VERSION "created by Milan Hutera"

NS_ :

BS_:

BU_: WorkGrp ECU Drive Display Primary PTOLKeypad ServiceTool Joystick1 Catalyst Shuttle Attachment CABKeypad ACDKeypad Joystick2 Joystick3

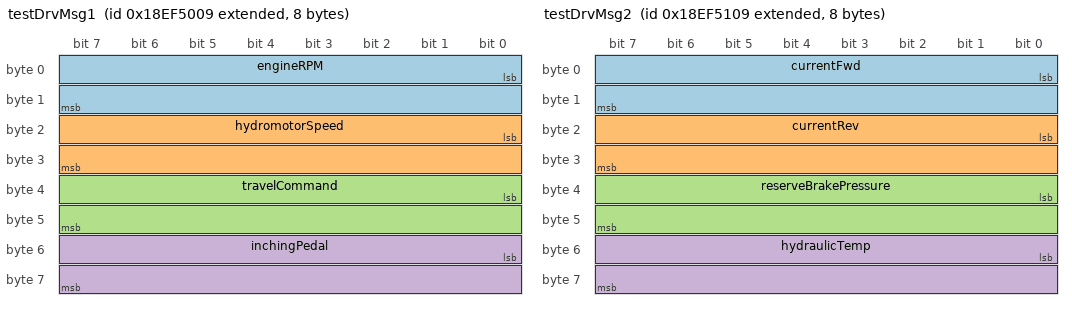
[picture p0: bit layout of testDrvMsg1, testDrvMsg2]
BO_ 2565820425 testDrvMsg1: 8 Drive
 SG_ engineRPM : 0|16@1+ (1,0.00) [0.00|65535.0] "-" ServiceTool
 SG_ hydromotorSpeed : 16|16@1+ (1,0.00) [0.00|65535.0] "-" ServiceTool
 SG_ travelCommand : 32|16@1+ (0.01,0.00) [0.00|655.35] "-" ServiceTool
 SG_ inchingPedal : 48|16@1+ (0.01,0.00) [0.00|655.35] "-" ServiceTool

BO_ 2565820681 testDrvMsg2: 8 Drive
 SG_ currentFwd : 0|16@1+ (0.01,0.00) [0.00|655.35] "-" ServiceTool
 SG_ currentRev : 16|16@1+ (0.01,0.00) [0.00|655.35] "-" ServiceTool
 SG_ reserveBrakePressure : 32|16@1+ (0.01,0.00) [0.00|655.35] "-" ServiceTool
 SG_ hydraulicTemp : 48|16@1+ (0.01,0.00) [0.00|655.35] "-" ServiceTool

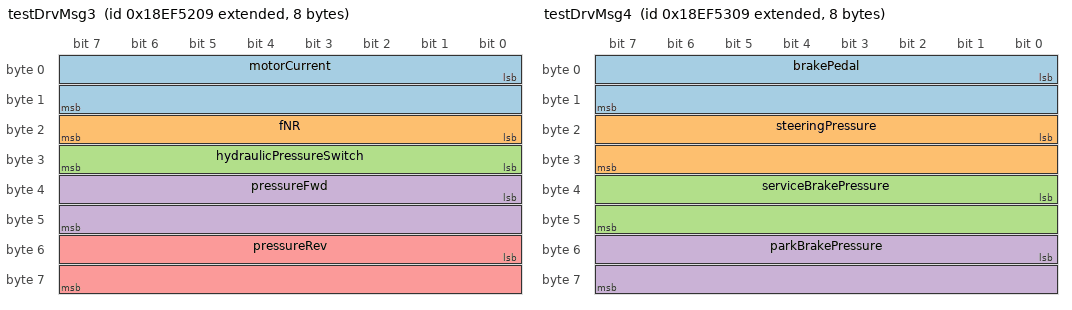
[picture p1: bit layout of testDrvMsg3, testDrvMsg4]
BO_ 2565820937 testDrvMsg3: 8 Drive
 SG_ motorCurrent : 0|16@1+ (0.01,0.00) [0.00|655.35] "-" ServiceTool
 SG_ fNR : 16|8@1+ (1,0.00) [0.00|255.0] "-" ServiceTool
 SG_ hydraulicPressureSwitch : 24|8@1+ (1,0.00) [0.00|255.0] "-" ServiceTool
 SG_ pressureFwd : 32|16@1+ (0.01,0.00) [0.00|655.35] "-" ServiceTool
 SG_ pressureRev : 48|16@1+ (0.01,0.00) [0.00|655.35] "-" ServiceTool

BO_ 2565821193 testDrvMsg4: 8 Drive
 SG_ brakePedal : 0|16@1+ (0.01,0.00) [0.00|655.35] "-" ServiceTool
 SG_ steeringPressure : 16|16@1+ (0.01,0.00) [0.00|655.35] "-" ServiceTool
 SG_ serviceBrakePressure : 32|16@1+ (0.01,0.00) [0.00|655.35] "-" ServiceTool
 SG_ parkBrakePressure : 48|16@1+ (0.01,0.00) [0.00|655.35] "-" ServiceTool

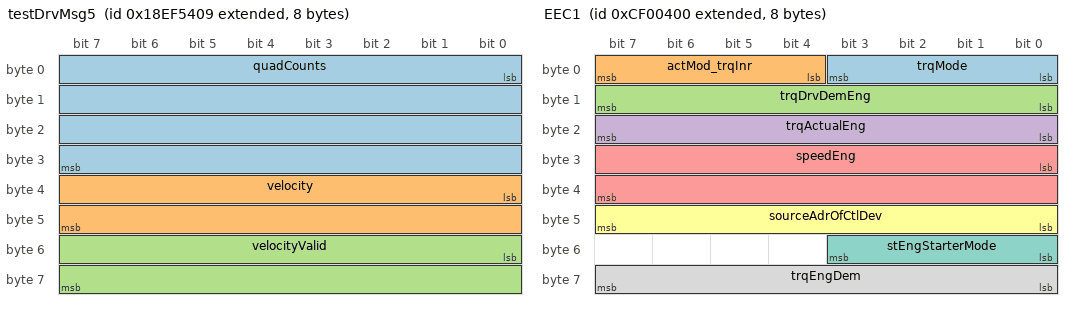
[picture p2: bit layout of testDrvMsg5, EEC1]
BO_ 2565821449 testDrvMsg5: 8 Drive
 SG_ quadCounts : 0|32@1+ (1.0,-2147483648) [-2147483648|21474] "-" ServiceTool
 SG_ velocity : 32|16@1+ (0.01,-60.00) [-60.00|60.00] "-" ServiceTool
 SG_ velocityValid : 48|16@1+ (0.01,0.00) [0.00|655.35] "-" ServiceTool

BO_ 2565821705 testDrvMsg6: 8 Drive
 SG_ quadErrorCounts : 0|32@1+ (1.0,-2147483648) [-2147483648|21474] "-" ServiceTool
 SG_ encoderACount : 32|32@1+ (1.0,-2147483648) [-2147483648|21474] "-" ServiceTool

BO_ 2364539904 EEC1: 8 ECU
 SG_ trqMode : 0|4@1+ (1,0) [0|0] "-" Primary
 SG_ actMod_trqInr : 4|4@1- (0.125,0.0) [0.0|0.875] "" Primary
 SG_ trqDrvDemEng : 8|8@1+ (1,-125.0) [-125.0|125.0] "%" Primary
 SG_ trqActualEng : 16|8@1+ (10.0,-1250.0) [-1250.0|1250.0] "Nm" Primary
 SG_ speedEng : 24|16@1+ (0.125,0.0) [0.0|8031.88] "" Primary
 SG_ sourceAdrOfCtlDev : 40|8@1+ (1,0) [0|0] "-" Primary
 SG_ stEngStarterMode : 48|4@1+ (1,0) [0|0] "-" Primary
 SG_ trqEngDem : 56|8@1+ (1,0.0) [0.0|125.0] "%" Primary

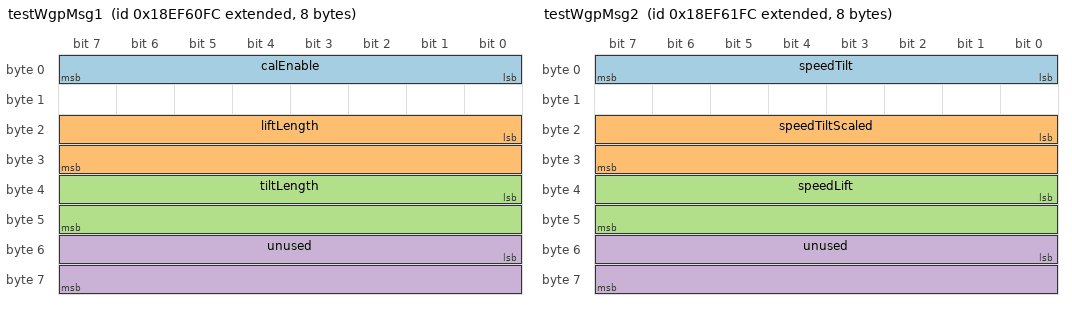
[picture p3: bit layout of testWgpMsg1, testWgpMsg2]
BO_ 2565824764 testWgpMsg1: 8 WorkGrp
 SG_ calEnable : 0|8@1+ (1,0.00) [0.00|255.0] "-" ServiceTool
 SG_ liftLength : 16|16@1+ (1,0.00) [0.00|65535.0] "-" ServiceTool
 SG_ tiltLength : 32|16@1+ (1,0.00) [0.00|65535.0] "-" ServiceTool
 SG_ unused : 48|16@1+ (0.01,0.00) [0.00|655.35] "-" ServiceTool

BO_ 2565825020 testWgpMsg2: 8 WorkGrp
 SG_ speedTilt : 0|8@1+ (1,0.00) [0.00|255.0] "-" ServiceTool
 SG_ speedTiltScaled : 16|16@1+ (0.1,0.00) [0.00|6553.5] "-" ServiceTool
 SG_ speedLift : 32|16@1+ (0.1,0.00) [0.00|6553.5] "-" ServiceTool
 SG_ unused : 48|16@1+ (0.01,0.00) [0.00|655.35] "-" ServiceTool

CM_ BO_ 2364539904 "Electronic Engine Control";

CM_ SG_ 2364539904 trqMode "Engine Torque Mode";
CM_ SG_ 2364539904 actMod_trqInr "Actual Engine : Percent Torque High Resolution";
CM_ SG_ 2364539904 trqDrvDemEng "Driver's Demand Engine : Percent Torque";
CM_ SG_ 2364539904 trqActualEng "Actual Engine : Percent Torque";
CM_ SG_ 2364539904 speedEng "Engine Speed";
CM_ SG_ 2364539904 sourceAdrOfCtlDev "Source Address of Controlling Device for Engine Control";
CM_ SG_ 2364539904 stEngStarterMode "Engine Starter mode";
CM_ SG_ 2364539904 trqEngDem "Engine Demand : Percent Torque";

BA_DEF_ SG_  "SigType" ENUM  "Default","Range","RangeSigned","ASCII","Discrete","Control","ReferencePGN","DTC","StringDelimiter","StringLength","StringLengthControl";
BA_DEF_ SG_  "GenSigEVName" STRING ;
BA_DEF_ SG_  "GenSigILSupport" ENUM  "No","Yes";
BA_DEF_ SG_  "GenSigSendType" ENUM  "Cyclic","OnWrite","OnWriteWithRepetition","OnChange","OnChangeWithRepetition","IfActive","IfActiveWithRepetition","NoSigSendType";
BA_DEF_ BO_  "GenMsgILSupport" ENUM  "No","Yes";
BA_DEF_ BU_  "NmStationAddress" INT 0 255;
BA_DEF_ BO_  "GenMsgSendType" ENUM  "cyclic","SendNow","IfActive","onRequest","Ident","counterValidator","NotUsed","NotUsed","noMsgSendType","enabled";
BA_DEF_ BO_  "Port_Drive" ENUM  "CAN_PORT_1","CAN_PORT_2","CAN_PORT_3","CAN_PORT_4","CAN_PORT_5","CAN_PORT_6","CAN_PORT_7","CAN_PORT_8","None";
BA_DEF_ BO_  "Port_ServiceTool" ENUM  "CAN_PORT_1","CAN_PORT_2","CAN_PORT_3","CAN_PORT_4","CAN_PORT_5","CAN_PORT_6","CAN_PORT_7","CAN_PORT_8","None";
BA_DEF_ BO_  "Port_ECU" ENUM  "CAN_PORT_1","CAN_PORT_2","CAN_PORT_3","CAN_PORT_4","CAN_PORT_5","CAN_PORT_6","CAN_PORT_7","CAN_PORT_8","None";
BA_DEF_ BO_  "Port_Primary" ENUM  "CAN_PORT_1","CAN_PORT_2","CAN_PORT_3","CAN_PORT_4","CAN_PORT_5","CAN_PORT_6","CAN_PORT_7","CAN_PORT_8","None";
BA_DEF_ BO_  "Port_WorkGrp" ENUM  "CAN_PORT_1","CAN_PORT_2","CAN_PORT_3","CAN_PORT_4","CAN_PORT_5","CAN_PORT_6","CAN_PORT_7","CAN_PORT_8","None";

BA_DEF_ BO_  "GenMsgRequestable" INT 0 1;
BA_DEF_ BO_  "GenMsgCycleTime" INT 0 3600000;
BA_DEF_  "DBName" STRING ;
BA_DEF_  "BusType" STRING ;
BA_DEF_  "ProtocolType" STRING ;
BA_DEF_ BO_  "VFrameFormat" ENUM  "StandardCAN","ExtendedCAN","reserved","J1939PG";
BA_DEF_DEF_  "SigType" "Default";
BA_DEF_DEF_  "GenSigEVName" "Env@Nodename_@Signame";
BA_DEF_DEF_  "GenSigILSupport" "Yes";
BA_DEF_DEF_  "GenSigSendType" "NoSigSendType";
BA_DEF_DEF_  "Port_Drive" "None";
BA_DEF_DEF_  "Port_ServiceTool" "None";
BA_DEF_DEF_  "Port_ECU" "None";
BA_DEF_DEF_  "Port_Primary" "None";
BA_DEF_DEF_  "Port_WorkGrp" "None";

BA_DEF_DEF_  "GenMsgILSupport" "Yes";
BA_DEF_DEF_  "NmStationAddress" 254;
BA_DEF_DEF_  "GenMsgSendType" "noMsgSendType";
BA_DEF_DEF_  "GenMsgRequestable" 1;
BA_DEF_DEF_  "GenMsgCycleTime" 0;
BA_DEF_DEF_  "DBName" "";
BA_DEF_DEF_  "BusType" "CAN";
BA_DEF_DEF_  "ProtocolType" "J1939";
BA_DEF_DEF_  "VFrameFormat" "J1939PG";
BA_ "DBName" "CWL";
BA_ "NmStationAddress" BU_ WorkGrp 252;
BA_ "NmStationAddress" BU_ ECU 0;
BA_ "NmStationAddress" BU_ Drive 9;
BA_ "NmStationAddress" BU_ Display 65;
BA_ "NmStationAddress" BU_ Primary 176;
BA_ "NmStationAddress" BU_ PTOLKeypad 55;
BA_ "NmStationAddress" BU_ ServiceTool 179;
BA_ "NmStationAddress" BU_ Joystick1 236;
BA_ "NmStationAddress" BU_ Catalyst 163;
BA_ "NmStationAddress" BU_ Shuttle 240;
BA_ "NmStationAddress" BU_ Attachment 180;
BA_ "NmStationAddress" BU_ CABKeypad 194;
BA_ "NmStationAddress" BU_ ACDKeypad 195;
BA_ "NmStationAddress" BU_ Joystick2 51;
BA_ "NmStationAddress" BU_ Joystick3 237;

BA_ "Port_Drive" BO_ 2565820425 0;
BA_ "Port_ServiceTool" BO_ 2565820425 0;
BA_ "Port_Drive" BO_ 2565820681 0;
BA_ "Port_ServiceTool" BO_ 2565820681 0;
BA_ "Port_Drive" BO_ 2565820937 0;
BA_ "Port_ServiceTool" BO_ 2565820937 0;
BA_ "Port_Drive" BO_ 2565821193 0;
BA_ "Port_ServiceTool" BO_ 2565821193 0;
BA_ "Port_Drive" BO_ 2565821449 0;
BA_ "Port_ServiceTool" BO_ 2565821449 0;
BA_ "Port_Drive" BO_ 2565821705 0;
BA_ "Port_ServiceTool" BO_ 2565821705 0;
BA_ "Port_ECU" BO_ 2364539904 0;
BA_ "Port_Primary" BO_ 2364539904 0;
BA_ "Port_WorkGrp" BO_ 2565824764 0;
BA_ "Port_ServiceTool" BO_ 2565824764 0;
BA_ "Port_WorkGrp" BO_ 2565825020 0;
BA_ "Port_ServiceTool" BO_ 2565825020 0;

BA_ "GenMsgSendType" BO_ 2565820425 0;
BA_ "GenMsgCycleTime" BO_ 2565820425 100;
BA_ "GenMsgSendType" BO_ 2565820681 0;
BA_ "GenMsgCycleTime" BO_ 2565820681 100;
BA_ "GenMsgSendType" BO_ 2565820937 0;
BA_ "GenMsgCycleTime" BO_ 2565820937 100;
BA_ "GenMsgSendType" BO_ 2565821193 0;
BA_ "GenMsgCycleTime" BO_ 2565821193 100;
BA_ "GenMsgSendType" BO_ 2565821449 0;
BA_ "GenMsgCycleTime" BO_ 2565821449 100;
BA_ "GenMsgSendType" BO_ 2565821705 0;
BA_ "GenMsgCycleTime" BO_ 2565821705 10;
BA_ "GenMsgSendType" BO_ 2364539904 0;
BA_ "GenMsgCycleTime" BO_ 2364539904 100;
BA_ "GenMsgSendType" BO_ 2565824764 0;
BA_ "GenMsgCycleTime" BO_ 2565824764 50;
BA_ "GenMsgSendType" BO_ 2565825020 0;
BA_ "GenMsgCycleTime" BO_ 2565825020 50;

VAL_ 2364539904 trqMode 0 "Idling" 1 "AccPedalGovernorActive" 2 "CruiseControl" 3 "PowerTakeOffGovernor" 4 "RoadSpeedLimiter" 5 "ASR_Control" 6 "TransmissionControl" 7 "ABS_control" 8 "TorqueLimiter" 9 "HighSpeedGovernor" 10 "EngineRetarderControl" 12 "Fuel_Limitation" 13 "VCU_PTO_trq_ctl_lim_active" 14 "VCU_PTO_spd_ctl_lim_active" 15 "NotAvailiable" ;
VAL_ 2364539904 sourceAdrOfCtlDev 0 "EDC_is_controlling_torque" 3 "TSC1TE_or_TSC1TR" 11 "TSC1AE_or_TSC1AR" 16 "TSC1DE_or_TSC1DR" 33 "TSC1VE_or_TSC1VR" 36 "TSC1PE" ;
VAL_ 2364539904 stEngStarterMode 0 "Start_not_requested" 1 "Starter_active_gear_not_engaged" 2 "Starter_active_gear_engaged" 3 "Starter_finished" 4 "Engine_already_running" 5 "Engine_not_ready_for_start" 6 "Driveline_engaged" 7 "Starter_inhibit_due_to_IMMO" 13 "Starter_inhibit_reason_unknown" 14 "Error" 15 "Not_available" ;
